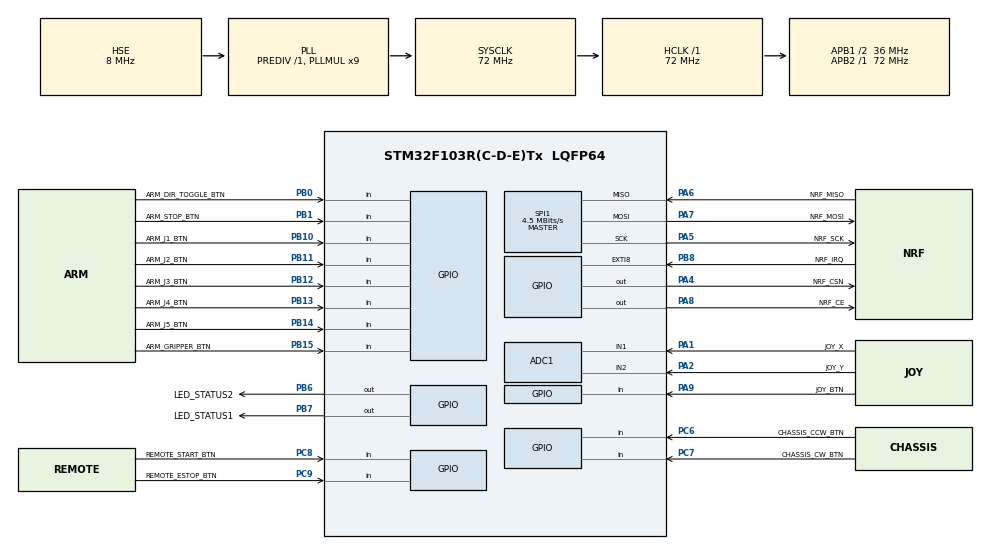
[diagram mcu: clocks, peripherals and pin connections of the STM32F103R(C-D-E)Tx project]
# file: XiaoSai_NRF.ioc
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ADC1.Channel-1\#ChannelRegularConversion=ADC_CHANNEL_1
ADC1.Channel-2\#ChannelRegularConversion=ADC_CHANNEL_2
ADC1.ContinuousConvMode=ENABLE
ADC1.NbrOfConversion=2
ADC1.NbrOfConversionFlag=1
ADC1.Rank-1\#ChannelRegularConversion=1
ADC1.Rank-2\#ChannelRegularConversion=2
ADC1.SamplingTime-1\#ChannelRegularConversion=ADC_SAMPLETIME_55CYCLES_5
ADC1.SamplingTime-2\#ChannelRegularConversion=ADC_SAMPLETIME_55CYCLES_5
ADC1.ScanConvMode=ADC_SCAN_ENABLE
ADC1.master=1
Dma.ADC1.0.Direction=DMA_PERIPH_TO_MEMORY
Dma.ADC1.0.Instance=DMA1_Channel1
Dma.ADC1.0.MemDataAlignment=DMA_MDATAALIGN_HALFWORD
Dma.ADC1.0.MemInc=DMA_MINC_ENABLE
Dma.ADC1.0.Mode=DMA_CIRCULAR
Dma.ADC1.0.PeriphDataAlignment=DMA_PDATAALIGN_HALFWORD
Dma.ADC1.0.PeriphInc=DMA_PINC_DISABLE
Dma.ADC1.0.Priority=DMA_PRIORITY_LOW
Dma.Request0=ADC1
Mcu.Family=STM32F1
Mcu.Name=STM32F103R(C-D-E)Tx
Mcu.Package=LQFP64
NVIC.DMA1_Channel1_IRQn=true\:0\:0\:false\:false\:true\:false\:true\:true
NVIC.EXTI9_5_IRQn=true\:0\:0\:false\:false\:true\:true\:true\:true
NVIC.PriorityGroup=NVIC_PRIORITYGROUP_4
PA1.GPIO_Label=JOY_X
PA1.Signal=ADCx_IN1
PA2.GPIO_Label=JOY_Y
PA2.Signal=ADCx_IN2
PA13.Mode=Serial_Wire
PA13.Signal=SYS_JTMS-SWDIO
PA14.Mode=Serial_Wire
PA14.Signal=SYS_JTCK-SWCLK
PA4.GPIO_Label=NRF_CSN
PA4.PinState=GPIO_PIN_SET
PA4.Signal=GPIO_Output
PA5.GPIO_Label=NRF_SCK
PA5.Mode=Full_Duplex_Master
PA5.Signal=SPI1_SCK
PA6.GPIO_Label=NRF_MISO
PA6.Mode=Full_Duplex_Master
PA6.Signal=SPI1_MISO
PA7.GPIO_Label=NRF_MOSI
PA7.Mode=Full_Duplex_Master
PA7.Signal=SPI1_MOSI
PA8.GPIO_Label=NRF_CE
PA8.PinState=GPIO_PIN_RESET
PA8.Signal=GPIO_Output
PA9.GPIO_Label=JOY_BTN
PA9.GPIO_PuPd=GPIO_PULLUP
PA9.Signal=GPIO_Input
PB0.GPIO_Label=ARM_DIR_TOGGLE_BTN
PB0.GPIO_PuPd=GPIO_PULLUP
PB0.Signal=GPIO_Input
PB1.GPIO_Label=ARM_STOP_BTN
PB1.GPIO_PuPd=GPIO_PULLUP
PB1.Signal=GPIO_Input
PB10.GPIO_Label=ARM_J1_BTN
PB10.GPIO_PuPd=GPIO_PULLUP
PB10.Signal=GPIO_Input
PB11.GPIO_Label=ARM_J2_BTN
PB11.GPIO_PuPd=GPIO_PULLUP
PB11.Signal=GPIO_Input
PB12.GPIO_Label=ARM_J3_BTN
PB12.GPIO_PuPd=GPIO_PULLUP
PB12.Signal=GPIO_Input
PB13.GPIO_Label=ARM_J4_BTN
PB13.GPIO_PuPd=GPIO_PULLUP
PB13.Signal=GPIO_Input
PB14.GPIO_Label=ARM_J5_BTN
PB14.GPIO_PuPd=GPIO_PULLUP
PB14.Signal=GPIO_Input
PB15.GPIO_Label=ARM_GRIPPER_BTN
PB15.GPIO_PuPd=GPIO_PULLUP
PB15.Signal=GPIO_Input
PB6.GPIO_Label=LED_STATUS2
PB6.Signal=GPIO_Output
PB7.GPIO_Label=LED_STATUS1
PB7.Signal=GPIO_Output
PB8.GPIO_Label=NRF_IRQ
PB8.GPIO_ModeDefaultEXTI=GPIO_MODE_IT_FALLING
PB8.GPIO_PuPd=GPIO_PULLUP
PB8.Signal=GPXTI8
PC6.GPIO_Label=CHASSIS_CCW_BTN
PC6.GPIO_PuPd=GPIO_PULLUP
PC6.Signal=GPIO_Input
PC7.GPIO_Label=CHASSIS_CW_BTN
PC7.GPIO_PuPd=GPIO_PULLUP
PC7.Signal=GPIO_Input
PC8.GPIO_Label=REMOTE_START_BTN
PC8.GPIO_PuPd=GPIO_PULLUP
PC8.Signal=GPIO_Input
PC9.GPIO_Label=REMOTE_ESTOP_BTN
PC9.GPIO_PuPd=GPIO_PULLUP
PC9.Signal=GPIO_Input
PD0-OSC_IN.Mode=HSE-External-Oscillator
PD0-OSC_IN.Signal=RCC_OSC_IN
PD1-OSC_OUT.Mode=HSE-External-Oscillator
PD1-OSC_OUT.Signal=RCC_OSC_OUT
ProjectManager.HeapSize=0x200
ProjectManager.StackSize=0x400
ProjectManager.TargetToolchain=CMake
RCC.ADCPresc=RCC_ADCPCLK2_DIV6
RCC.AHBFreq_Value=72000000
RCC.APB1CLKDivider=RCC_HCLK_DIV2
RCC.APB1Freq_Value=36000000
RCC.APB1TimFreq_Value=72000000
RCC.APB2Freq_Value=72000000
RCC.APB2TimFreq_Value=72000000
RCC.HCLKFreq_Value=72000000
RCC.PLLMUL=RCC_PLL_MUL9
RCC.PLLSourceVirtual=RCC_PLLSOURCE_HSE
RCC.SYSCLKFreq_VALUE=72000000
RCC.SYSCLKSource=RCC_SYSCLKSOURCE_PLLCLK
RCC.USBFreq_Value=72000000
SH.ADCx_IN1.0=ADC1_IN1,IN1
SH.ADCx_IN2.0=ADC1_IN2,IN2
SPI1.BaudRatePrescaler=SPI_BAUDRATEPRESCALER_16
SPI1.CalculateBaudRate=4.5 MBits/s
SPI1.Direction=SPI_DIRECTION_2LINES
SPI1.Mode=SPI_MODE_MASTER
SPI1.VirtualType=VM_MASTER
VP_IWDG_VS_IWDG.Mode=IWDG_Activate
board=custom

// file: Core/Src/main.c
/* USER CODE BEGIN Header */
/**
  ******************************************************************************
  * @file           : main.c
  * @brief          : Main program body
  ******************************************************************************
  * @attention
  *
  * Copyright (c) 2026 STMicroelectronics.
  * All rights reserved.
  *
  * This software is licensed under terms that can be found in the LICENSE file
  * in the root directory of this software component.
  * If no LICENSE file comes with this software, it is provided AS-IS.
  *
  ******************************************************************************
  */
/* USER CODE END Header */
#include "main.h"
#include "adc.h"
#include "dma.h"
#include "iwdg.h"
#include "spi.h"
#include "gpio.h"

/* USER CODE BEGIN Includes */
#include "hh_app.h"
/* USER CODE END Includes */

void SystemClock_Config(void);

int main(void)
{

  /* MCU Configuration--------------------------------------------------------*/

  /* Reset of all peripherals, Initializes the Flash interface and the Systick. */
  HAL_Init();

  /* Configure the system clock */
  SystemClock_Config();

  /* Initialize all configured peripherals */
  MX_GPIO_Init();
  MX_DMA_Init();
  MX_ADC1_Init();
  MX_SPI1_Init();
  MX_IWDG_Init();
  /* USER CODE BEGIN 2 */
  // 断点暂停时看门狗也暂停，调试时不会被复位
  __HAL_DBGMCU_FREEZE_IWDG();

  // 不阻塞：NRF 上电等待和配置重试都在 HhApp_Update 里按时间处理
  HhApp_Init();
  /* USER CODE END 2 */

  /* Infinite loop */
  while (1)
  {

    /* USER CODE BEGIN 3 */
    HhApp_Update();
  }
  /* USER CODE END 3 */
}

void SystemClock_Config(void)
{
  RCC_OscInitTypeDef RCC_OscInitStruct = {0};
  RCC_ClkInitTypeDef RCC_ClkInitStruct = {0};
  RCC_PeriphCLKInitTypeDef PeriphClkInit = {0};

  /** Initializes the RCC Oscillators according to the specified parameters
  * in the RCC_OscInitTypeDef structure.
  */
  RCC_OscInitStruct.OscillatorType = RCC_OSCILLATORTYPE_LSI|RCC_OSCILLATORTYPE_HSE;
  RCC_OscInitStruct.HSEState = RCC_HSE_ON;
  RCC_OscInitStruct.HSEPredivValue = RCC_HSE_PREDIV_DIV1;
  RCC_OscInitStruct.HSIState = RCC_HSI_ON;
  RCC_OscInitStruct.LSIState = RCC_LSI_ON;
  RCC_OscInitStruct.PLL.PLLState = RCC_PLL_ON;
  RCC_OscInitStruct.PLL.PLLSource = RCC_PLLSOURCE_HSE;
  RCC_OscInitStruct.PLL.PLLMUL = RCC_PLL_MUL9;
  if (HAL_RCC_OscConfig(&RCC_OscInitStruct) != HAL_OK)
  {
    Error_Handler();
  }

  /** Initializes the CPU, AHB and APB buses clocks
  */
  RCC_ClkInitStruct.ClockType = RCC_CLOCKTYPE_HCLK|RCC_CLOCKTYPE_SYSCLK
                              |RCC_CLOCKTYPE_PCLK1|RCC_CLOCKTYPE_PCLK2;
  RCC_ClkInitStruct.SYSCLKSource = RCC_SYSCLKSOURCE_PLLCLK;
  RCC_ClkInitStruct.AHBCLKDivider = RCC_SYSCLK_DIV1;
  RCC_ClkInitStruct.APB1CLKDivider = RCC_HCLK_DIV2;
  RCC_ClkInitStruct.APB2CLKDivider = RCC_HCLK_DIV1;

  if (HAL_RCC_ClockConfig(&RCC_ClkInitStruct, FLASH_LATENCY_2) != HAL_OK)
  {
    Error_Handler();
  }
  PeriphClkInit.PeriphClockSelection = RCC_PERIPHCLK_ADC;
  PeriphClkInit.AdcClockSelection = RCC_ADCPCLK2_DIV6;
  if (HAL_RCCEx_PeriphCLKConfig(&PeriphClkInit) != HAL_OK)
  {
    Error_Handler();
  }
}

void Error_Handler(void)
{
  __disable_irq();
  while (1)
  {
  }
}
